# nrf9230_celldsp register map
Vendor: Nordic Semiconductor; Series: nRF92; File version: 1
Registers are 32-bit, read-write, reset 0x0 unless marked. A register's access mark holds for its fields unless they carry their own. Offsets are from the block's base; [hi:lo] are bit positions; lines under a group give offsets from that group; {n}, {i} and the like mark numbered series.

## DECTSYNC — GENERIC
Base 0x4500F000
0x00 TASKS_GENERICTASK wo — Generic event
  [0] TASKS_GENERICTASK
    1=Trigger task
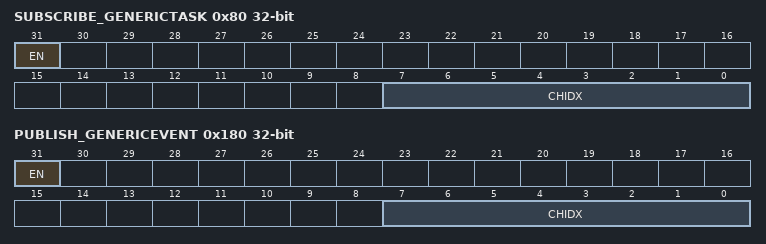
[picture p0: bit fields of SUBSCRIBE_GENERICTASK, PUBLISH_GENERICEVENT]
0x80 SUBSCRIBE_GENERICTASK — Subscribe configuration for task GENERICTASK
  [31] EN
    0=Disabled (Disable subscription); 1=Enabled (Enable subscription)
  [7:0] CHIDX — DPPI channel that task GENERICTASK will subscribe to
0x100 EVENTS_GENERICEVENT — Generic event
  [0] EVENTS_GENERICEVENT
    0=NotGenerated (Event not generated); 1=Generated (Event generated)
0x180 PUBLISH_GENERICEVENT — Publish configuration for event GENERICEVENT
  [31] EN
    0=Disabled (Disable publishing); 1=Enabled (Enable publishing)
  [7:0] CHIDX — DPPI channel that event GENERICEVENT will publish to
0x300 INTEN — Enable or disable interrupt
  [0] GENERICEVENT — Enable or disable interrupt for event GENERICEVENT
    0=Disabled; 1=Enabled
0x304 INTENSET — Enable interrupt
  [0] GENERICEVENT — Write '1' to enable interrupt for event GENERICEVENT
    on read: 0=Disabled (Read: Disabled); 1=Enabled (Read: Enabled) | on write: 1=Set (Enable)
0x308 INTENCLR — Disable interrupt
  [0] GENERICEVENT — Write '1' to disable interrupt for event GENERICEVENT
    on read: 0=Disabled (Read: Disabled); 1=Enabled (Read: Enabled) | on write: 1=Clear (Disable)

## CPUCONF — CPU Configuration
Base 0x45011000
0x00 TASKS_ERASECACHE wo — Erase the caches used by the CPU.
  [0] TASKS_ERASECACHE
    1=Trigger task
0x500 INITSVTOR — Initial value of the secure VTOR (Vector Table Offset Register) after CPU reset.
  [31:0] INITSVTOR — Initial value of the VTOR.
0x504 INITNSVTOR — Initial value of the non-secure VTOR (Vector Table Offset Register).
  [31:0] INITNSVTOR — Initial value of the VTOR.
0x508 CPUSTART — Enable for starting the CPU
  [0] EN — Enable to start the CPU.
    0=Stopped (CPU stopped.); 1=Started (CPU started.)
0x50C CPUWAIT — Enable for the CPU wait.
  [0] EN — Enable to the CPU wait.
    0=Disabled (CPU is not waiting.); 1=Enabled (CPU is waiting.)

## MEMCONF — Memory configuration
Base 0x45012000
{0x500+0x10*i} POWER[{i}] (i=0..1) group — Unspecified
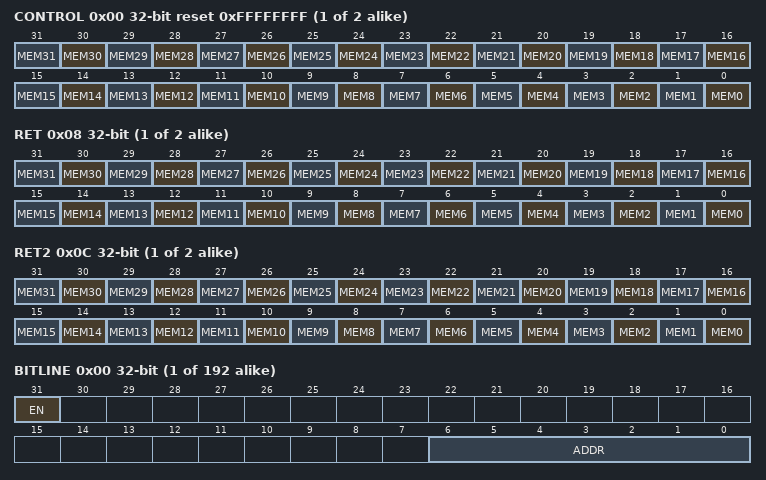
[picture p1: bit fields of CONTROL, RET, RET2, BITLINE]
  0x00 CONTROL reset 0xFFFFFFFF — Description cluster: Control memory block power.
    [all] fields
      0=Off (Power down); 1=On (Power up)
    [n] MEM{n} (n=0..31) — Keep the memory block MEM[{n}] on or off when in System ON mode.
  0x08 RET — Description cluster: RAM retention for RAM [n].
    [all] fields
      0=Off (Retention off); 1=On (Retention on)
    [n] MEM{n} (n=0..31) — Keep the RAM block MEM[{n}] retained when the parent power domain of the RAM is off.
  0x0C RET2 — Description cluster: RAM retention for the second bank in the RAM block
    [all] fields
      0=Off (Retention off); 1=On (Retention on)
    [n] MEM{n} (n=0..31) — Keep the second bank in RAM block MEM[{n}] retained when parent power domain of the RAM is off.
{0x600+4i} REPAIR[{i}] (i=0..191) group — Unspecified
  0x00 BITLINE — Description cluster: Repair configuration for RAM blocks.
    [31] EN — Enable bitline repair
      0=Disabled (Repair disabled.); 1=Enabled (Repair enabled.)
    [6:0] ADDR — Repair address of the bitline
{0x900+4i} BLOCKTYPE[{i}] (i=0..63) group — Unspecified
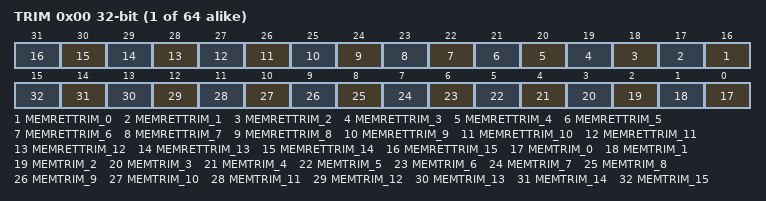
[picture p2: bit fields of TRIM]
  0x00 TRIM — Description cluster: Trim configuration for the memory block types.
    [n+16] MEMRETTRIM_{n} (n=0..15) — Trimming for retention mode for decreased leakage. Must be kept active in RAM retention mode.
    [n] MEMTRIM_{n} (n=0..15) — Read/write margin trim.

## DSPCTRL — DSP control
Base 0x45014000
0x400 CPUID ro reset 0x5 — CPU domain ID
  [3:0] CPUID
0x404 ENABLEIRQIPCBLOCKING — ENABLEIRQIPCBLOCKING should be enabled before DSP starts its shutdown or deepsleep routine. Register is automatically cleared when DSP wakes up. ENABLEIRQIPCBLOCKING blocks the IPC interrupt wake-up mechanism and the IRQ propagating to DSP interrupt input. If the IPC interrupt is not blocked, DSP can enter to unknown state, if IPC IRQ occurs during deepsleep or shutdown sequence.
  [0] ENABLEIRQIPCBLOCKING — Enable for blocking the IPC interrupt wake-up mechanism
    0=Disabled (Blocking disabled); 1=Enabled (Blocking enabled)
0x408 ENABLEFORCEOFF — Control for forcing off the DSP clock requesting
  [0] ENABLEFORCEOFF
    0=Disabled (DSP clock request force off disabled); 1=Enabled (DSP clock request force off enabled)
{0x410+4i} MASTERPRIORITY[{i}] (i=0..15) reset 0xFFFFFFFF — Description collection: Control priority for AXI master connected to the local AXI bus matrix. NOTE: actual reset values vary across the register array.
  [3:0] PRIORITY — Master n priority level
{0x450+4i} SLAVEPRIORITY[{i}] (i=0..6) — Description collection: Control priority for AXI slaves connected to the local AXI bus matrix
  [2:0] PRIORITY — Slave n priority level
0x46C DECTFRONTENDSEL — Control for selecting DECTSYNC timing signals from LTEFE or POSFE
  [1:0] DECTFRONTENDSEL
    0=LTEFE (DECTSYNC control from LTEFE); 1=WIFIB (DECTSYNC control from POSFE (WIFIB)); 2=WIFIGN (DECTSYNC control from POSFE (WIFIGN)); 3=NotUsed (Reserved field)
